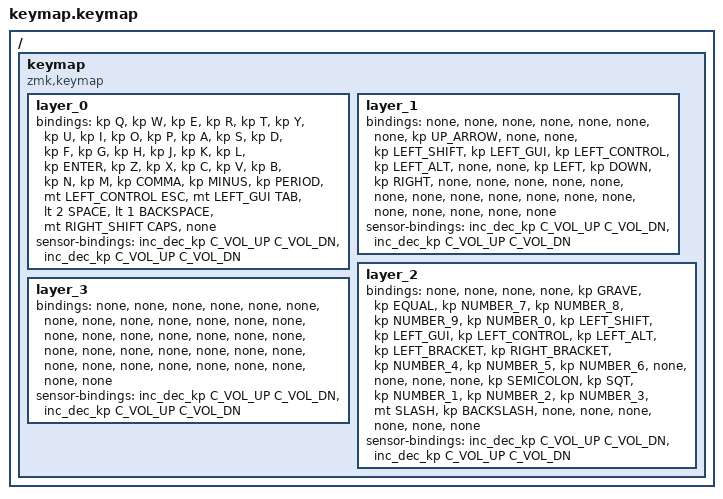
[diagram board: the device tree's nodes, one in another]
#include <behaviors.dtsi>
#include <dt-bindings/zmk/keys.h>

/ {
    keymap {
        compatible = "zmk,keymap";

        layer_0 {
            bindings = <
&kp Q
&kp W
&kp E
&kp R
&kp T
&kp Y
&kp U
&kp I
&kp O
&kp P
&kp A
&kp S
&kp D
&kp F
&kp G
&kp H
&kp J
&kp K
&kp L
&kp ENTER
&kp Z
&kp X
&kp C
&kp V
&kp B
&kp N
&kp M
&kp COMMA
&kp MINUS
&kp PERIOD
&mt LEFT_CONTROL ESC
&mt LEFT_GUI TAB
&lt 2 SPACE
&lt 1 BACKSPACE
&mt RIGHT_SHIFT CAPS
&none
            >;

            sensor-bindings = <&inc_dec_kp C_VOL_UP C_VOL_DN &inc_dec_kp C_VOL_UP C_VOL_DN>;
        };

        layer_1 {
            bindings = <
&none
&none
&none
&none
&none
&none
&none
&kp UP_ARROW
&none
&none
&kp LEFT_SHIFT
&kp LEFT_GUI
&kp LEFT_CONTROL
&kp LEFT_ALT
&none
&none
&kp LEFT
&kp DOWN
&kp RIGHT
&none
&none
&none
&none
&none
&none
&none
&none
&none
&none
&none
&none
&none
&none
&none
&none
&none
            >;

            sensor-bindings = <&inc_dec_kp C_VOL_UP C_VOL_DN &inc_dec_kp C_VOL_UP C_VOL_DN>;
        };

        layer_2 {
            bindings = <
&none
&none
&none
&none
&kp GRAVE
&kp EQUAL
&kp NUMBER_7
&kp NUMBER_8
&kp NUMBER_9
&kp NUMBER_0
&kp LEFT_SHIFT
&kp LEFT_GUI
&kp LEFT_CONTROL
&kp LEFT_ALT
&kp LEFT_BRACKET
&kp RIGHT_BRACKET
&kp NUMBER_4
&kp NUMBER_5
&kp NUMBER_6
&none
&none
&none
&none
&kp SEMICOLON
&kp SQT
&kp NUMBER_1
&kp NUMBER_2
&kp NUMBER_3
&mt SLASH
&kp BACKSLASH
&none
&none
&none
&none
&none
&none
            >;

            sensor-bindings = <&inc_dec_kp C_VOL_UP C_VOL_DN &inc_dec_kp C_VOL_UP C_VOL_DN>;
        };

        layer_3 {
            bindings = <
&none
&none
&none
&none
&none
&none
&none
&none
&none
&none
&none
&none
&none
&none
&none
&none
&none
&none
&none
&none
&none
&none
&none
&none
&none
&none
&none
&none
&none
&none
&none
&none
&none
&none
&none
&none
            >;

            sensor-bindings = <&inc_dec_kp C_VOL_UP C_VOL_DN &inc_dec_kp C_VOL_UP C_VOL_DN>;
        };
    };
};
